# TM4C1233H6PGE register map
Vendor: Texas Instruments; File version: 11073
CPU: CM4 r1p2, little endian, no MPU, no FPU, 0x3 interrupt priority bits, 0x0 interrupts
Registers are 32-bit, read-write, no defined reset value unless marked. A register's access mark holds for its fields unless they carry their own. Offsets are from the block's base; [hi:lo] are bit positions; {n}, {i} and the like mark numbered series.

## WATCHDOG0 — Register map for WATCHDOG0 peripheral
Base 0x40000000; register names take the prefix WATCHDOG0
0x00 LOAD — Watchdog Load
  [31:0] WDT_LOAD — Watchdog Load Value
0x04 VALUE — Watchdog Value
  [31:0] WDT_VALUE
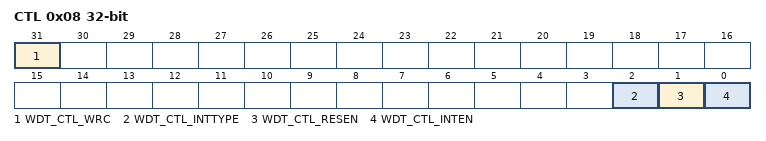
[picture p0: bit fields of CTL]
0x08 CTL — Watchdog Control
  [31] WDT_CTL_WRC — Write Complete
  [2] WDT_CTL_INTTYPE — Watchdog Interrupt Type
  [1] WDT_CTL_RESEN — Watchdog Reset Enable
  [0] WDT_CTL_INTEN — Watchdog Interrupt Enable
0x0C ICR wo — Watchdog Interrupt Clear
  [31:0] WDT_ICR
0x10 RIS — Watchdog Raw Interrupt Status
  [0] WDT_RIS_WDTRIS
0x14 MIS — Watchdog Masked Interrupt Status
  [0] WDT_MIS_WDTMIS
0x418 TEST — Watchdog Test
  [8] WDT_TEST_STALL — Watchdog Stall Enable
0xC00 LOCK — Watchdog Lock
  [31:0] WDT_LOCK
    0=WDT_LOCK_UNLOCKED (Unlocked); 1=WDT_LOCK_LOCKED (Locked); 0x1ACCE551=WDT_LOCK_UNLOCK (Unlocks the watchdog timer)

## WATCHDOG1 — Register map for WATCHDOG0 peripheral
Base 0x40001000; register names take the prefix WATCHDOG1
Registers as WATCHDOG0.

## SSI0 — Register map for SSI0 peripheral
Base 0x40008000; register names take the prefix SSI0
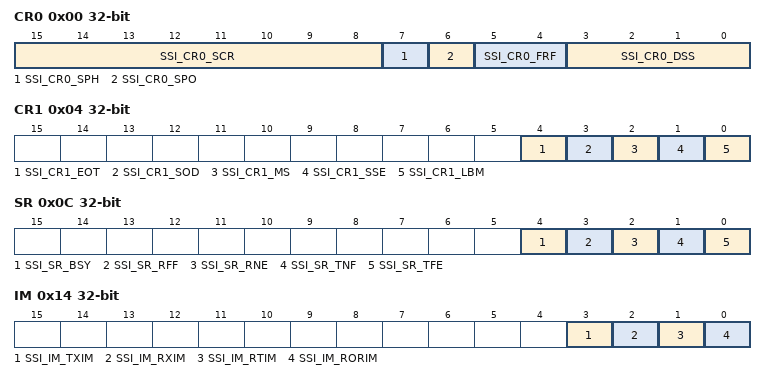
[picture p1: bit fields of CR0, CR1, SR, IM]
0x00 CR0 — SSI Control 0
  [15:8] SSI_CR0_SCR — SSI Serial Clock Rate
  [7] SSI_CR0_SPH — SSI Serial Clock Phase
  [6] SSI_CR0_SPO — SSI Serial Clock Polarity
  [5:4] SSI_CR0_FRF — SSI Frame Format Select
    0=SSI_CR0_FRF_MOTO (Freescale SPI Frame Format); 1=SSI_CR0_FRF_TI (Texas Instruments Synchronous Serial Frame Format); 2=SSI_CR0_FRF_NMW (MICROWIRE Frame Format)
  [3:0] SSI_CR0_DSS — SSI Data Size Select
    {v}={v+1}-bit data (v=3..15)
0x04 CR1 — SSI Control 1
  [4] SSI_CR1_EOT — End of Transmission
  [3] SSI_CR1_SOD — SSI Slave Mode Output Disable
  [2] SSI_CR1_MS — SSI Master/Slave Select
  [1] SSI_CR1_SSE — SSI Synchronous Serial Port Enable
  [0] SSI_CR1_LBM — SSI Loopback Mode
0x08 DR — SSI Data
  [15:0] SSI_DR_DATA — SSI Receive/Transmit Data
0x0C SR — SSI Status
  [4] SSI_SR_BSY — SSI Busy Bit
  [3] SSI_SR_RFF — SSI Receive FIFO Full
  [2] SSI_SR_RNE — SSI Receive FIFO Not Empty
  [1] SSI_SR_TNF — SSI Transmit FIFO Not Full
  [0] SSI_SR_TFE — SSI Transmit FIFO Empty
0x10 CPSR — SSI Clock Prescale
  [7:0] SSI_CPSR_CPSDVSR — SSI Clock Prescale Divisor
0x14 IM — SSI Interrupt Mask
  [3] SSI_IM_TXIM — SSI Transmit FIFO Interrupt Mask
  [2] SSI_IM_RXIM — SSI Receive FIFO Interrupt Mask
  [1] SSI_IM_RTIM — SSI Receive Time-Out Interrupt Mask
  [0] SSI_IM_RORIM — SSI Receive Overrun Interrupt Mask
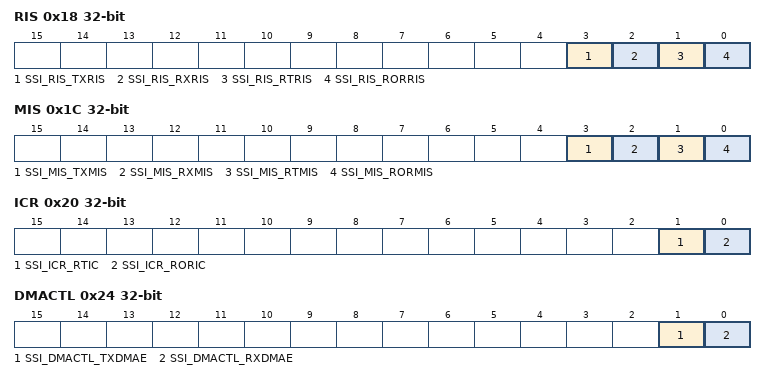
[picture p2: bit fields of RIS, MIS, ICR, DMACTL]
0x18 RIS — SSI Raw Interrupt Status
  [3] SSI_RIS_TXRIS — SSI Transmit FIFO Raw Interrupt Status
  [2] SSI_RIS_RXRIS — SSI Receive FIFO Raw Interrupt Status
  [1] SSI_RIS_RTRIS — SSI Receive Time-Out Raw Interrupt Status
  [0] SSI_RIS_RORRIS — SSI Receive Overrun Raw Interrupt Status
0x1C MIS — SSI Masked Interrupt Status
  [3] SSI_MIS_TXMIS — SSI Transmit FIFO Masked Interrupt Status
  [2] SSI_MIS_RXMIS — SSI Receive FIFO Masked Interrupt Status
  [1] SSI_MIS_RTMIS — SSI Receive Time-Out Masked Interrupt Status
  [0] SSI_MIS_RORMIS — SSI Receive Overrun Masked Interrupt Status
0x20 ICR wo — SSI Interrupt Clear
  [1] SSI_ICR_RTIC — SSI Receive Time-Out Interrupt Clear
  [0] SSI_ICR_RORIC — SSI Receive Overrun Interrupt Clear
0x24 DMACTL — SSI DMA Control
  [1] SSI_DMACTL_TXDMAE — Transmit DMA Enable
  [0] SSI_DMACTL_RXDMAE — Receive DMA Enable
0xFC8 CC — SSI Clock Configuration
  [3:0] SSI_CC_CS — SSI Baud Clock Source
    0=SSI_CC_CS_SYSPLL (Either the system clock (if the PLL bypass is in effect) or the PLL output (default)); 5=SSI_CC_CS_PIOSC (PIOSC)

## SSI1 — Register map for SSI0 peripheral
Base 0x40009000; register names take the prefix SSI1
Registers as SSI0.

## SSI2 — Register map for SSI0 peripheral
Base 0x4000A000; register names take the prefix SSI2
Registers as SSI0.

## SSI3 — Register map for SSI0 peripheral
Base 0x4000B000; register names take the prefix SSI3
Registers as SSI0.
